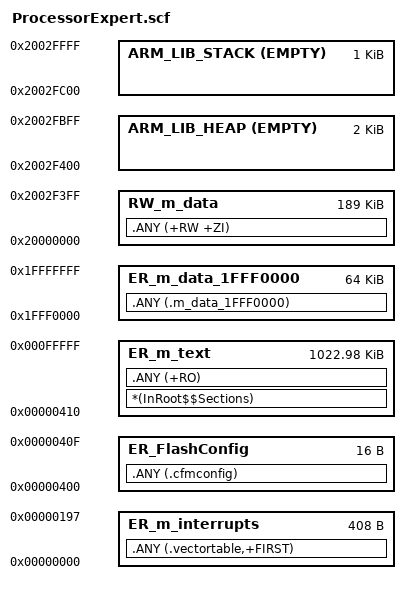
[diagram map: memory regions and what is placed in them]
#! armcc -E
; ###################################################################
;##
;##     This component module is generated by Processor Expert. Do not modify it.
;##                                                
;##     Filename  : ProcessorExpert.scf                
;##                                                
;##     Project   : FRDM-K64F_BlinkLed_Keil                   
;##                                                
;##     Processor : MK64FN1M0VLQ12                    
;##                                                
;##     Compiler  : Keil ARM C/C++ Compiler                    
;##                                                
;##     Date/Time : 2014-11-08, 08:56, # CodeGen: 17                     
;##                                                
;##     Abstract  :                                
;##                                                
;##     This file is used by the linker. It describes files to be linked,
;##     memory ranges, stack size, etc. For detailed description about linker
;##     command files see compiler documentation. This file is generated by default.
;##     You can switch off generation by setting the property "Generate linker file = no"
;##     in the "Build options" tab of the CPU component and then modify this file as needed.
;##
;##                                                
;## ###################################################################


#define m_interrupts_start              0x00000000
#define m_interrupts_size               0x00000198

#define m_text_start                    0x00000410
#define m_text_size                     0x000FFBF0

#define m_data_1FFF0000_start           0x1FFF0000
#define m_data_1FFF0000_size            0x00010000

#define m_data_start                    0x20000000
#define m_data_size                     0x00030000

#define FlashConfig_start               0x00000400
#define FlashConfig_size                0x00000010

/*-Sizes-*/
#define stack_size                      0x0400
#define heap_size                       0x0800

LR_m_text m_text_start m_text_size  {  ; load region size_region
  ER_m_text m_text_start m_text_size  { ; load address = execution address
   *(InRoot$$Sections)
   .ANY (+RO)
  }
  RW_m_data m_data_start m_data_size-stack_size-heap_size  { ; RW data
   .ANY (+RW +ZI)
  }
  ARM_LIB_STACK m_data_start+m_data_size EMPTY -stack_size { ; Stack region growing down
  }
  ARM_LIB_HEAP m_data_start+m_data_size-stack_size-heap_size EMPTY heap_size { ; Heap region growing up
  }
}

LR_m_interrupts m_interrupts_start m_interrupts_size  {
  ER_m_interrupts m_interrupts_start m_interrupts_size  { ; load address = execution address
   .ANY (.vectortable,+FIRST)
  }
}
LR_FlashConfig FlashConfig_start FlashConfig_size  {
  ER_FlashConfig FlashConfig_start FlashConfig_size  { ; load address = execution address
   .ANY (.cfmconfig)
  }
}

LR_m_data_1FFF0000 m_data_1FFF0000_start m_data_1FFF0000_size  {
  ER_m_data_1FFF0000 m_data_1FFF0000_start m_data_1FFF0000_size  { ; load address = execution address
   .ANY (.m_data_1FFF0000)
  }
}


